# STM32WL3R register map
File version: 1.0
CPU: CM0+ r0p0, little endian, MPU, no FPU, 4 interrupt priority bits
Registers are 32-bit, read-write, reset 0x0 unless marked. A register's access mark holds for its fields unless they carry their own. Offsets are from the block's base; lines under a group give offsets from that group; [hi:lo] are bit positions; {n}, {i} and the like mark numbered series; 'fields as' and 'values as' point back to an identical list; <NAME> marks a mode.

## Memory map
0x40000000 SYSCFG size 0x48 — SYSCFG address block description
0x40001000 FLASH size 0x58 — FLASH address block description
0x40002000 TIMER2 size 0x6C — TIMER2 address block description
0x40003000 IWDG size 0x14 — IWDG address block description
0x40004000 RTC size 0x58 — RTC address block description
0x40005000 TIMER16 size 0x6C — TIMER16 address block description
0x40008000 DBGMCU size 0xC — DBGMCU address block description
0x41000000 I2C1 size 0x2C — I2C1 address block description
0x41002000 SPI3 size 0x24 — SPI3 address block description
0x41004000 USART size 0x30 — USART address block description
0x41005000 LPUART size 0x30 — LPUART address block description
0x41006000 ADC size 0x68 — ADC address block description
0x48000000 GPIOA size 0x2C — GPIOA address block description
0x48100000 GPIOB size 0x2C — GPIOB address block description
0x48200000 CRC size 0x18 — CRC address block description
0x48400000 RCC size 0xB0 — RCC address block description
0x48500000 PWRC size 0xA8 — PWRC address block description
0x48600000 RNG size 0x1000 — RNG address block description
0x48700000 DMA size 0xA4 — DMA address block description
0x48800000 DMAMUX size 0x20 — DMAMUX address block description
0x48900000 AES3 size 0x60 — AES3 address block description
0x49000000 RADIO size 0x400 — RADIO_REG_BLOCK address block description
0x49000400 STATIC size 0x100 — STATIC_REG_BLOCK address block description
0x49000500 DYNAMIC size 0x100 — DYNAMIC_REG_BLOCK address block description
0x49000600 STATUS size 0x100 — STATUS_REG_BLOCK address block description
0x49000700 MISC size 0x80 — MISC_REG_BLOCK address block description
0x49000780 RETAINED size 0x80 — RETAINED_REG_BLOCK address block description

## Interrupts
0 FLASH — FLASH interrupt
1 RCC — RCC interrupt
2 PVD (PWRC) — PVD interrupt
3 I2C1 — I2C1 interrupt
7 SPI3 — SPI3 interrupt
8 USART1 (USART) — USART1 interrupt
9 LPUART1 (LPUART) — Low Power UART interrupt
10 TIM2 (TIMER2) — TIM2 interrupt
11 RTC — RTC interrupt
12 ADC — ADC interrupt
13 AES (AES3) — AES interrupt
15 GPIOA — GPIOA interrupt
16 GPIOB — GPIOB interrupt
17 DMA — DMA interrupt
20 MRSUBG_BUSY (RADIO) — MRSUBG_BUSY interrupt
21 MRSUBG (RADIO) — MRSUBG interrupt
22 MRSUBG_TX_RX_SEQUENCE (RADIO) — MR_SUBG TX/RX Sequence interrupt
23 MRSUBG_TIMER_CPU_WKUP (RETAINED) — CPU Wakeup interrupt
24 MRSUBG_WKUP (RADIO) — MR_SUBG Wakeup interrupt
26 TIM16 (TIMER16) — TIM16 interrupt

## AES3 — AES3 address block description
Base 0x48900000
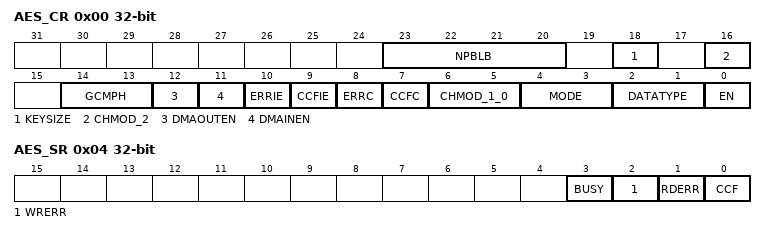
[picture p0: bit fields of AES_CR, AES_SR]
0x00 AES_CR
  [23:20] NPBLB — Number of Padding Bytes in Last Block of payload.
  [18] KEYSIZE — Key Size selection.
  [16] CHMOD_2 — Chaining mode selection, bit [2]
  [14:13] GCMPH — GCM or CCM Phase selection
  [12] DMAOUTEN — DMA Output Enable
  [11] DMAINEN — DMA Input Enable
  [10] ERRIE — Error Interrupt Enable
  [9] CCFIE — CCF flag Interrupt Enable
  [8] ERRC — Error clear
  [7] CCFC — Computation Complete Flag Clear
  [6:5] CHMOD_1_0 — AES Chaining Mode selection
  [4:3] MODE — AES operating mode
  [2:1] DATATYPE — Data type selection
  [0] EN — AES IP enable
0x04 AES_SR ro
  [3] BUSY — Busy flag
  [2] WRERR — Write error flag
  [1] RDERR — Read error flag
  [0] CCF — Computation complete flag
0x08 AES_DINR
  [31:0] DINR — One of four 32-bit words of a 128-bit input data block being written into the peripheral
0x0C AES_DOUTR ro
  [31:0] DOUTR — One of four 32-bit words of a 128-bit output data block being read from the
{0x10+4i} AES_KEYR{i} (i=0..3) — AES_KEYRx register
  [31:0] KEY — Cryptographic key, bits [31:0]
{0x20+4i} AES_IVR{i} (i=0..3) — AES_IVRx register
  [31:0] IVI — initialization vector register (LSB IVR [31:0])
{0x20+4i} AES_KEYR{i} (i=4..7)
  [31:0] KEY — Cryptographic key, bits [31:0]
{0x40+4i} AES_SUSP{i} (i=0..7) — AES_SUSPx register
  [31:0] SUSP — These registers contain the complete internal register states of the AES processor when the

## Notices in the file
Copyright (c) 2025 STMicroelectronics.
SPDX-License-Identifier: Apache-2.0
Licensed under the Apache License, Version 2.0 (the "License");
you may not use this file except in compliance with the License.
You may obtain a copy of the License at
http://www.apache.org/licenses/LICENSE-2.0
Unless required by applicable law or agreed to in writing, software
distributed under the License is distributed on an "AS IS" BASIS,
WITHOUT WARRANTIES OR CONDITIONS OF ANY KIND, either express or implied.
See the License for the specific language governing permissions and
limitations under the License.
